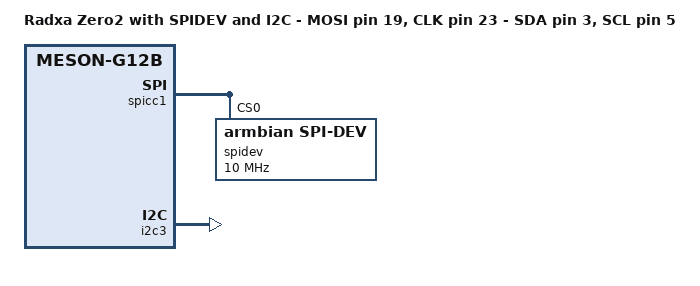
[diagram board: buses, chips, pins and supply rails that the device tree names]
// SPDX-License-Identifier: (GPL-2.0+ OR MIT)

/dts-v1/;

#include "meson-g12b-radxa-zero2.dts"

/ {
	model = "Radxa Zero2 with SPIDEV and I2C - MOSI pin 19, CLK pin 23 - SDA pin 3, SCL pin 5";
};

&spicc1 {
	pinctrl-0 = <&spicc1_pins &spicc1_ss0_pins>;
	pinctrl-names = "default";
	#address-cells = <1>;
	#size-cells = <0>;
	status = "okay";
	spidev@0 {
		compatible = "armbian,spi-dev";
		status = "okay";
		reg = <0>;
		spi-max-frequency = <10000000>;
	};
};

&i2c3 {
	status = "okay";
	pinctrl-0 = <&i2c3_sck_a_pins &i2c3_sda_a_pins>;
	pinctrl-names = "default";
};
